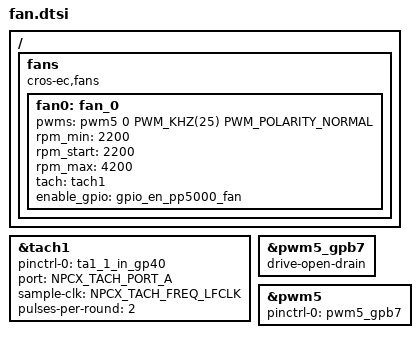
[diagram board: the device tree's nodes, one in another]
/* Copyright 2023 The ChromiumOS Authors
 * Use of this source code is governed by a BSD-style license that can be
 * found in the LICENSE file.
 */

/ {
	fans {
		compatible = "cros-ec,fans";

		fan0: fan_0 {
			pwms = <&pwm5 0 PWM_KHZ(25) PWM_POLARITY_NORMAL>;
			rpm_min = <2200>;
			rpm_start = <2200>;
			rpm_max = <4200>;
			tach = <&tach1>;
			enable_gpio = <&gpio_en_pp5000_fan>;
		};
	};
};

/* Tachemeter for fan speed measurement */
&tach1 {
	status = "okay";
	pinctrl-0 = <&ta1_1_in_gp40>;
	pinctrl-names = "default";
	port = <NPCX_TACH_PORT_A>; /* port-A is selected */
	sample-clk = <NPCX_TACH_FREQ_LFCLK>; /* Use LFCLK as sampling clock */
	pulses-per-round = <2>; /* number of pulses per round of encoder */
};

&pwm5_gpb7 {
	drive-open-drain;
};

&pwm5 {
	status = "okay";
	pinctrl-0 = <&pwm5_gpb7>;
	pinctrl-names = "default";
};
